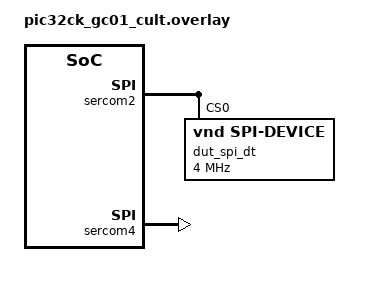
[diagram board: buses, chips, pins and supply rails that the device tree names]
/*
 * Copyright (c) 2026 Microchip Technology Inc.
 *
 * SPDX-License-Identifier: Apache-2.0
 */

&sercom2 {
	status = "okay";
	compatible = "microchip,sercom-g1-spi";
	dipo = <3>;
	dopo = <0>;

	#address-cells = <1>;
	#size-cells = <0>;

	pinctrl-0 = <&sercom2_spi_default>;
	pinctrl-names = "default";

	dut_spi_dt: test-spi-dev@0 {
		compatible = "vnd,spi-device";
		reg = <0>;
		spi-max-frequency = <4000000>;
	};
};

dut_spis: &sercom4 {
	status = "okay";
	compatible = "microchip,sercom-g1-spi";
	dipo = <2>;
	dopo = <0>;

	#address-cells = <1>;
	#size-cells = <0>;

	pinctrl-0 = <&sercom4_spi_default>;
	pinctrl-names = "default";
};
